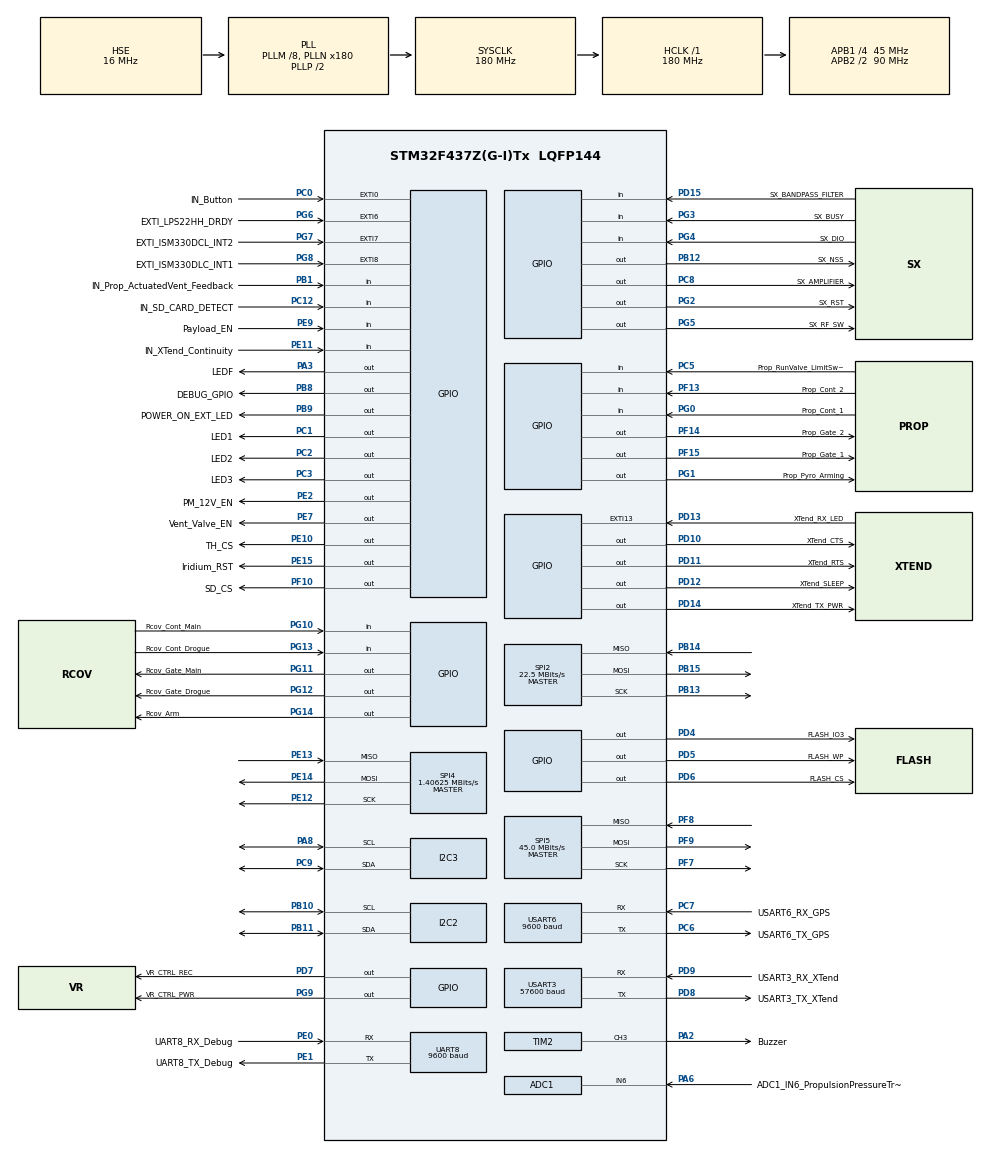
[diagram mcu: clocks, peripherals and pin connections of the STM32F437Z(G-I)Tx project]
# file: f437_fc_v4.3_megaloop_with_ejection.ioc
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ADC1.Channel-0\#ChannelRegularConversion=ADC_CHANNEL_6
ADC1.ClockPrescaler=ADC_CLOCK_SYNC_PCLK_DIV4
ADC1.ContinuousConvMode=DISABLE
ADC1.DMAContinuousRequests=DISABLE
ADC1.ExternalTrigConv=ADC_SOFTWARE_START
ADC1.ExternalTrigConvEdge=ADC_EXTERNALTRIGCONVEDGE_NONE
ADC1.InjNumberOfConversion=0
ADC1.NbrOfConversion=1
ADC1.NbrOfConversionFlag=1
ADC1.Rank-0\#ChannelRegularConversion=1
ADC1.SamplingTime-0\#ChannelRegularConversion=ADC_SAMPLETIME_28CYCLES
ADC1.master=1
Dma.ADC1.3.Direction=DMA_PERIPH_TO_MEMORY
Dma.ADC1.3.FIFOMode=DMA_FIFOMODE_DISABLE
Dma.ADC1.3.Instance=DMA2_Stream0
Dma.ADC1.3.MemDataAlignment=DMA_MDATAALIGN_HALFWORD
Dma.ADC1.3.MemInc=DMA_MINC_ENABLE
Dma.ADC1.3.Mode=DMA_NORMAL
Dma.ADC1.3.PeriphDataAlignment=DMA_PDATAALIGN_HALFWORD
Dma.ADC1.3.PeriphInc=DMA_PINC_DISABLE
Dma.ADC1.3.Priority=DMA_PRIORITY_LOW
Dma.Request0=USART3_RX
Dma.Request1=USART3_TX
Dma.Request2=USART6_RX
Dma.Request3=ADC1
Dma.USART3_RX.0.Direction=DMA_PERIPH_TO_MEMORY
Dma.USART3_RX.0.FIFOMode=DMA_FIFOMODE_DISABLE
Dma.USART3_RX.0.Instance=DMA1_Stream1
Dma.USART3_RX.0.MemDataAlignment=DMA_MDATAALIGN_BYTE
Dma.USART3_RX.0.MemInc=DMA_MINC_ENABLE
Dma.USART3_RX.0.Mode=DMA_NORMAL
Dma.USART3_RX.0.PeriphDataAlignment=DMA_PDATAALIGN_BYTE
Dma.USART3_RX.0.PeriphInc=DMA_PINC_DISABLE
Dma.USART3_RX.0.Priority=DMA_PRIORITY_VERY_HIGH
Dma.USART3_TX.1.Direction=DMA_MEMORY_TO_PERIPH
Dma.USART3_TX.1.FIFOMode=DMA_FIFOMODE_DISABLE
Dma.USART3_TX.1.Instance=DMA1_Stream3
Dma.USART3_TX.1.MemDataAlignment=DMA_MDATAALIGN_BYTE
Dma.USART3_TX.1.MemInc=DMA_MINC_ENABLE
Dma.USART3_TX.1.Mode=DMA_NORMAL
Dma.USART3_TX.1.PeriphDataAlignment=DMA_PDATAALIGN_BYTE
Dma.USART3_TX.1.PeriphInc=DMA_PINC_DISABLE
Dma.USART3_TX.1.Priority=DMA_PRIORITY_MEDIUM
Dma.USART6_RX.2.Direction=DMA_PERIPH_TO_MEMORY
Dma.USART6_RX.2.FIFOMode=DMA_FIFOMODE_DISABLE
Dma.USART6_RX.2.Instance=DMA2_Stream1
Dma.USART6_RX.2.MemDataAlignment=DMA_MDATAALIGN_BYTE
Dma.USART6_RX.2.MemInc=DMA_MINC_ENABLE
Dma.USART6_RX.2.Mode=DMA_NORMAL
Dma.USART6_RX.2.PeriphDataAlignment=DMA_PDATAALIGN_BYTE
Dma.USART6_RX.2.PeriphInc=DMA_PINC_DISABLE
Dma.USART6_RX.2.Priority=DMA_PRIORITY_MEDIUM
IWDG.Prescaler=IWDG_PRESCALER_64
IWDG.Reload=1000-1
Mcu.Family=STM32F4
Mcu.Name=STM32F437Z(G-I)Tx
Mcu.Package=LQFP144
NVIC.DMA1_Stream1_IRQn=true\:15\:0\:true\:false\:true\:false\:true
NVIC.DMA1_Stream3_IRQn=true\:0\:0\:true\:false\:true\:false\:true
NVIC.DMA2_Stream0_IRQn=true\:0\:0\:false\:false\:true\:false\:true
NVIC.DMA2_Stream1_IRQn=true\:0\:0\:false\:false\:true\:false\:true
NVIC.EXTI0_IRQn=true\:0\:0\:false\:false\:true\:true\:true
NVIC.PriorityGroup=NVIC_PRIORITYGROUP_4
NVIC.RTC_Alarm_IRQn=true\:0\:0\:false\:false\:true\:true\:true
NVIC.RTC_WKUP_IRQn=true\:0\:0\:false\:false\:true\:true\:true
NVIC.TIM3_IRQn=true\:0\:0\:true\:false\:true\:true\:true
NVIC.TIM8_BRK_TIM12_IRQn=true\:0\:0\:false\:false\:true\:true\:true
NVIC.TIM8_UP_TIM13_IRQn=true\:0\:0\:false\:false\:true\:true\:true
NVIC.USART3_IRQn=true\:0\:0\:false\:false\:true\:true\:true
NVIC.USART6_IRQn=true\:0\:0\:false\:false\:true\:true\:true
PA13.Mode=Trace_Asynchronous_SW
PA13.Signal=SYS_JTMS-SWDIO
PA14.Mode=Trace_Asynchronous_SW
PA14.Signal=SYS_JTCK-SWCLK
PA2.GPIO_Label=Buzzer
PA2.Signal=S_TIM2_CH3
PA3.GPIO_Label=LEDF
PA3.Signal=GPIO_Output
PA6.GPIO_Label=ADC1_IN6_PropulsionPressureTransducer
PA6.Signal=ADCx_IN6
PA8.GPIO_Pu=GPIO_PULLUP
PA8.Mode=I2C
PA8.Signal=I2C3_SCL
PB1.GPIO_Label=IN_Prop_ActuatedVent_Feedback
PB1.Signal=GPIO_Input
PB10.GPIO_Pu=GPIO_PULLUP
PB10.Mode=I2C
PB10.Signal=I2C2_SCL
PB11.GPIO_Pu=GPIO_PULLUP
PB11.Mode=I2C
PB11.Signal=I2C2_SDA
PB12.GPIO_Label=SX_NSS
PB12.GPIO_PuPd=GPIO_PULLUP
PB12.Signal=GPIO_Output
PB13.GPIO_PuPd=GPIO_PULLUP
PB13.Mode=Full_Duplex_Master
PB13.Signal=SPI2_SCK
PB14.GPIO_PuPd=GPIO_PULLUP
PB14.Mode=Full_Duplex_Master
PB14.Signal=SPI2_MISO
PB15.GPIO_PuPd=GPIO_PULLUP
PB15.Mode=Full_Duplex_Master
PB15.Signal=SPI2_MOSI
PB3.Mode=Trace_Asynchronous_SW
PB3.Signal=SYS_JTDO-SWO
PB8.GPIO_Label=DEBUG_GPIO
PB8.Signal=GPIO_Output
PB9.GPIO_Label=POWER_ON_EXT_LED
PB9.Signal=GPIO_Output
PC0.GPIO_Label=IN_Button
PC0.Signal=GPXTI0
PC1.GPIO_Label=LED1
PC1.Signal=GPIO_Output
PC12.GPIO_Label=IN_SD_CARD_DETECT
PC12.Signal=GPIO_Input
PC14/OSC32_IN.Mode=LSE-External-Oscillator
PC14/OSC32_IN.Signal=RCC_OSC32_IN
PC15/OSC32_OUT.Mode=LSE-External-Oscillator
PC15/OSC32_OUT.Signal=RCC_OSC32_OUT
PC2.GPIO_Label=LED2
PC2.Signal=GPIO_Output
PC3.GPIO_Label=LED3
PC3.Signal=GPIO_Output
PC5.GPIO_Label=Prop_RunValve_LimitSwitch
PC5.GPIO_PuPd=GPIO_PULLDOWN
PC5.Signal=GPIO_Input
PC6.GPIO_Label=USART6_TX_GPS
PC6.Mode=Asynchronous
PC6.Signal=USART6_TX
PC7.GPIO_Label=USART6_RX_GPS
PC7.Mode=Asynchronous
PC7.Signal=USART6_RX
PC8.GPIO_Label=SX_AMPLIFIER
PC8.Signal=GPIO_Output
PC9.GPIO_Pu=GPIO_PULLUP
PC9.Mode=I2C
PC9.Signal=I2C3_SDA
PD10.GPIO_Label=XTend_CTS
PD10.Signal=GPIO_Output
PD11.GPIO_Label=XTend_RTS
PD11.Signal=GPIO_Output
PD12.GPIO_Label=XTend_SLEEP
PD12.Signal=GPIO_Output
PD13.GPIO_Label=XTend_RX_LED
PD13.Signal=GPXTI13
PD14.GPIO_Label=XTend_TX_PWR
PD14.Signal=GPIO_Output
PD15.GPIO_Label=SX_BANDPASS_FILTER
PD15.Signal=GPIO_Input
PD4.GPIO_Label=FLASH_IO3
PD4.GPIO_PuPd=GPIO_PULLUP
PD4.GPIO_Speed=GPIO_SPEED_FREQ_HIGH
PD4.PinState=GPIO_PIN_SET
PD4.Signal=GPIO_Output
PD5.GPIO_Label=FLASH_WP
PD5.GPIO_PuPd=GPIO_PULLUP
PD5.GPIO_Speed=GPIO_SPEED_FREQ_HIGH
PD5.PinState=GPIO_PIN_SET
PD5.Signal=GPIO_Output
PD6.GPIO_Label=FLASH_CS
PD6.GPIO_ModeDefaultOutputPP=GPIO_MODE_OUTPUT_PP
PD6.GPIO_PuPd=GPIO_PULLUP
PD6.GPIO_Speed=GPIO_SPEED_FREQ_VERY_HIGH
PD6.PinState=GPIO_PIN_SET
PD6.Signal=GPIO_Output
PD7.GPIO_Label=VR_CTRL_REC
PD7.Signal=GPIO_Output
PD8.GPIO_Label=USART3_TX_XTend
PD8.Mode=Asynchronous
PD8.Signal=USART3_TX
PD9.GPIO_Label=USART3_RX_XTend
PD9.Mode=Asynchronous
PD9.Signal=USART3_RX
PE0.GPIO_Label=UART8_RX_Debug
PE0.Mode=Asynchronous
PE0.Signal=UART8_RX
PE1.GPIO_Label=UART8_TX_Debug
PE1.Mode=Asynchronous
PE1.Signal=UART8_TX
PE10.GPIO_Label=TH_CS
PE10.Signal=GPIO_Output
PE11.GPIO_Label=IN_XTend_Continuity
PE11.Signal=GPIO_Input
PE12.Mode=Full_Duplex_Master
PE12.Signal=SPI4_SCK
PE13.Mode=Full_Duplex_Master
PE13.Signal=SPI4_MISO
PE14.Mode=Full_Duplex_Master
PE14.Signal=SPI4_MOSI
PE15.GPIO_Label=Iridium_RST
PE15.Signal=GPIO_Output
PE2.GPIO_Label=PM_12V_EN
PE2.Signal=GPIO_Output
PE7.GPIO_Label=Vent_Valve_EN
PE7.Signal=GPIO_Output
PE9.GPIO_Label=Payload_EN
PE9.Signal=GPIO_Input
PF10.GPIO_Label=SD_CS
PF10.GPIO_PuPd=GPIO_PULLUP
PF10.GPIO_Speed=GPIO_SPEED_FREQ_VERY_HIGH
PF10.PinState=GPIO_PIN_SET
PF10.Signal=GPIO_Output
PF13.GPIO_Label=Prop_Cont_2
PF13.Signal=GPIO_Input
PF14.GPIO_Label=Prop_Gate_2
PF14.Signal=GPIO_Output
PF15.GPIO_Label=Prop_Gate_1
PF15.Signal=GPIO_Output
PF7.GPIO_PuPd=GPIO_PULLUP
PF7.GPIO_Speed=GPIO_SPEED_FREQ_VERY_HIGH
PF7.Mode=Full_Duplex_Master
PF7.Signal=SPI5_SCK
PF8.GPIO_PuPd=GPIO_PULLUP
PF8.GPIO_Speed=GPIO_SPEED_FREQ_VERY_HIGH
PF8.Mode=Full_Duplex_Master
PF8.Signal=SPI5_MISO
PF9.GPIO_PuPd=GPIO_PULLUP
PF9.GPIO_Speed=GPIO_SPEED_FREQ_VERY_HIGH
PF9.Mode=Full_Duplex_Master
PF9.Signal=SPI5_MOSI
PG0.GPIO_Label=Prop_Cont_1
PG0.Signal=GPIO_Input
PG1.GPIO_Label=Prop_Pyro_Arming
PG1.Signal=GPIO_Output
PG10.GPIO_Label=Rcov_Cont_Main
PG10.Signal=GPIO_Input
PG11.GPIO_Label=Rcov_Gate_Main
PG11.Signal=GPIO_Output
PG12.GPIO_Label=Rcov_Gate_Drogue
PG12.Signal=GPIO_Output
PG13.GPIO_Label=Rcov_Cont_Drogue
PG13.Signal=GPIO_Input
PG14.GPIO_Label=Rcov_Arm
PG14.Signal=GPIO_Output
PG2.GPIO_Label=SX_RST
PG2.Signal=GPIO_Output
PG3.GPIO_Label=SX_BUSY
PG3.Signal=GPIO_Input
PG4.GPIO_Label=SX_DIO
PG4.Signal=GPIO_Input
PG5.GPIO_Label=SX_RF_SW
PG5.Signal=GPIO_Output
PG6.GPIO_Label=EXTI_LPS22HH_DRDY
PG6.Signal=GPXTI6
PG7.GPIO_Label=EXTI_ISM330DCL_INT2
PG7.Signal=GPXTI7
PG8.GPIO_Label=EXTI_ISM330DLC_INT1
PG8.Signal=GPXTI8
PG9.GPIO_Label=VR_CTRL_PWR
PG9.Signal=GPIO_Output
PH0/OSC_IN.Mode=HSE-External-Oscillator
PH0/OSC_IN.Signal=RCC_OSC_IN
PH1/OSC_OUT.Mode=HSE-External-Oscillator
PH1/OSC_OUT.Signal=RCC_OSC_OUT
ProjectManager.HeapSize=0x200
ProjectManager.StackSize=0x400
ProjectManager.TargetToolchain=STM32CubeIDE
RCC.48MHZClocksFreq_Value=90000000
RCC.AHBFreq_Value=180000000
RCC.APB1CLKDivider=RCC_HCLK_DIV4
RCC.APB1Freq_Value=45000000
RCC.APB1TimFreq_Value=90000000
RCC.APB2CLKDivider=RCC_HCLK_DIV2
RCC.APB2Freq_Value=90000000
RCC.APB2TimFreq_Value=180000000
RCC.CortexFreq_Value=180000000
RCC.HCLKFreq_Value=180000000
RCC.HSE_VALUE=16000000
RCC.HSI_VALUE=16000000
RCC.PLLM=8
RCC.PLLN=180
RCC.PLLSourceVirtual=RCC_PLLSOURCE_HSE
RCC.SYSCLKFreq_VALUE=180000000
RCC.SYSCLKSource=RCC_SYSCLKSOURCE_PLLCLK
RCC.VCOOutputFreq_Value=360000000
RTC.Alarm=RTC_ALARM_A
RTC.Alarm_B=RTC_ALARM_B
RTC.Date=12
RTC.Hours=10
RTC.Minutes=20
RTC.Month=RTC_MONTH_FEBRUARY
RTC.Seconds=30
RTC.Seconds_A=15
RTC.Seconds_B=45
RTC.WakeUpCounter=1333-1
RTC.Year=21
SH.ADCx_IN6.0=ADC1_IN6,IN6
SH.S_TIM2_CH3.0=TIM2_CH3,PWM Generation3 CH3
SPI2.BaudRatePrescaler=SPI_BAUDRATEPRESCALER_2
SPI2.CalculateBaudRate=22.5 MBits/s
SPI2.Direction=SPI_DIRECTION_2LINES
SPI2.Mode=SPI_MODE_MASTER
SPI2.VirtualType=VM_MASTER
SPI4.BaudRatePrescaler=SPI_BAUDRATEPRESCALER_64
SPI4.CalculateBaudRate=1.40625 MBits/s
SPI4.Direction=SPI_DIRECTION_2LINES
SPI4.Mode=SPI_MODE_MASTER
SPI4.VirtualType=VM_MASTER
SPI5.BaudRatePrescaler=SPI_BAUDRATEPRESCALER_2
SPI5.CalculateBaudRate=45.0 MBits/s
SPI5.Direction=SPI_DIRECTION_2LINES
SPI5.Mode=SPI_MODE_MASTER
SPI5.VirtualType=VM_MASTER
TIM12.Period=1000-1
TIM12.Prescaler=900-1
TIM2.Channel-PWM\ Generation3\ CH3=TIM_CHANNEL_3
TIM2.Period=400-1
TIM2.Prescaler=90-1
TIM2.Pulse-PWM\ Generation3\ CH3=100
TIM2.TIM_MasterOutputTrigger=TIM_TRGO_UPDATE
TIM3.AutoReloadPreload=TIM_AUTORELOAD_PRELOAD_DISABLE
TIM3.Period=1000-1
TIM3.Prescaler=9000-1
TIM3.TIM_MasterOutputTrigger=TIM_TRGO_RESET
TIM4.Period=500-1
TIM4.Prescaler=9000-1
TIM4.TIM_MasterOutputTrigger=TIM_TRGO_UPDATE
TIM8.Period=200-1
TIM8.Prescaler=18000-1
TIM8.TIM_MasterOutputTrigger=TIM_TRGO_UPDATE
UART8.BaudRate=9600
UART8.VirtualMode=Asynchronous
USART3.BaudRate=57600
USART3.VirtualMode=VM_ASYNC
USART6.BaudRate=9600
USART6.VirtualMode=VM_ASYNC
VP_FATFS_VS_Generic.Mode=User_defined
VP_IWDG_VS_IWDG.Mode=IWDG_Activate
VP_RTC_VS_RTC_Activate.Mode=RTC_Enabled
VP_RTC_VS_RTC_Alarm_A_Intern.Mode=Alarm A
VP_RTC_VS_RTC_Alarm_B_Intern.Mode=Alarm B
VP_RTC_VS_RTC_Calendar.Mode=RTC_Calendar
VP_RTC_VS_RTC_WakeUp_intern.Mode=WakeUp
VP_TIM12_VS_ClockSourceINT.Mode=Internal
VP_TIM2_VS_ClockSourceINT.Mode=Internal
VP_TIM3_VS_ClockSourceINT.Mode=Internal
VP_TIM4_VS_ClockSourceINT.Mode=Internal
VP_TIM8_VS_ClockSourceINT.Mode=Internal
board=custom

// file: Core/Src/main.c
/* USER CODE BEGIN Header */
/**
  ******************************************************************************
  * @file           : main.c
  * @brief          : Main program body
  ******************************************************************************
  * @attention
  *
  * <h2><center>&copy; Copyright (c) 2022 STMicroelectronics.
  * All rights reserved.</center></h2>
  *
  * This software component is licensed by ST under BSD 3-Clause license,
  * the "License"; You may not use this file except in compliance with the
  * License. You may obtain a copy of the License at:
  *                        opensource.org/licenses/BSD-3-Clause
  *
  ******************************************************************************
  */
/* USER CODE END Header */
#include "main.h"
#include "adc.h"
#include "dma.h"
#include "fatfs.h"
#include "i2c.h"
#include "iwdg.h"
#include "rtc.h"
#include "spi.h"
#include "tim.h"
#include "usart.h"
#include "gpio.h"

/* USER CODE BEGIN Includes */

#include "string.h"

#include "i2c_sensor_functions.h"
#include "sd_card.h"
#include "gps.h"

// xtend radio
#include "xtend.h"

// others
#include "video_recorder.h"
#include "ejection.h"
#include "radio_commands.h"
#include "helpers.h"
#include "state_restoration.h"
#include "telemetry.h"
#include "startup.h"
#include "int_callbacks.h"
#include <iwdg.h>

#ifdef NEW_ADC
#include <MRT_ADS1015.h>
#endif

/* USER CODE END Includes */

/* USER CODE BEGIN PTD */

//#define DEBUG_MODE

/* USER CODE END PTD */

/* USER CODE BEGIN PV */

// flags
volatile uint8_t button_pressed = 0;
volatile uint8_t gps_dma_ready = 0;
volatile uint8_t xtend_time_to_transmit_flag = 0;
volatile uint8_t xtend_is_transmitting = 0;
volatile uint8_t save_sd_fsync = 0;
volatile uint8_t run_main_loop = 0;

extern volatile uint8_t vr_is_stop;
/* USER CODE END PV */

void SystemClock_Config(void);

/* USER CODE BEGIN 0 */

//TODO no print function
void no_print(char* text){
	return;
}

/* USER CODE END 0 */

int main(void)
{

  /* MCU Configuration--------------------------------------------------------*/

  /* Reset of all peripherals, Initializes the Flash interface and the Systick. */
  HAL_Init();

  /* Configure the system clock */
  SystemClock_Config();

  /* USER CODE BEGIN SysInit */
  __HAL_DBGMCU_FREEZE_IWDG();	// turn off IWDG and RTC during debugging
  __HAL_FREEZE_RTC_DBGMCU();
  /* USER CODE END SysInit */

  /* Initialize all configured peripherals */
  MX_GPIO_Init();
  MX_DMA_Init();
  MX_ADC1_Init();
  MX_I2C2_Init();
  MX_I2C3_Init();
  MX_SPI2_Init();
  MX_SPI4_Init();
  MX_SPI5_Init();
  MX_TIM2_Init();
  MX_UART8_Init();
  MX_USART3_UART_Init();
  MX_USART6_UART_Init();
  MX_FATFS_Init();
  MX_RTC_Init();
  MX_TIM4_Init();
  MX_TIM3_Init();
  MX_TIM8_Init();
  MX_IWDG_Init();
  MX_TIM12_Init();
  /* USER CODE BEGIN 2 */

  // *** IMPORTANT: DMA Init function must be called before peripheral init! *** //

  init_gpio_startup(__HAL_RCC_GET_FLAG(RCC_FLAG_IWDGRST));

  if (!(__HAL_RCC_GET_FLAG(RCC_FLAG_IWDGRST))) {
	  init_ejection_states();
	  init_backup_regs();
  }
  else {
	  __HAL_IWDG_RELOAD_COUNTER(&hiwdg);
	  restore_fc_states();

	  sprintf((char *)msg, "state = %d, ap = %d, ar = %d, alt_ground = %f",
			  state_flight, state_arm_prop, state_arm_rcov, alt_ground);
	  debug_tx_uart(msg);

	  // for debug
	  for (uint8_t i = 0; i < 3; i++) {
		  __HAL_IWDG_RELOAD_COUNTER(&hiwdg);
		  HAL_GPIO_WritePin(LED1_GPIO_Port, LED1_Pin, SET);
		  HAL_GPIO_WritePin(LED2_GPIO_Port, LED2_Pin, SET);
		  HAL_GPIO_WritePin(LED3_GPIO_Port, LED3_Pin, SET);
		  HAL_GPIO_WritePin(LEDF_GPIO_Port, LEDF_Pin, SET);

		  HAL_Delay(100);

		  HAL_GPIO_WritePin(LED1_GPIO_Port, LED1_Pin, RESET);
		  HAL_GPIO_WritePin(LED2_GPIO_Port, LED2_Pin, RESET);
		  HAL_GPIO_WritePin(LED3_GPIO_Port, LED3_Pin, RESET);
		  HAL_GPIO_WritePin(LEDF_GPIO_Port, LEDF_Pin, RESET);

		  HAL_Delay(100);
	  }
  }

  #ifndef USING_XTEND
	  set_hspi(hspi2);
	  set_NSS_pin(SX_NSS_GPIO_Port, SX_NSS_Pin);
	  set_BUSY_pin(SX_BUSY_GPIO_Port, SX_BUSY_Pin);
	  set_NRESET_pin(SX_RST_GPIO_Port, SX_RST_Pin);
	  set_DIO1_pin(SX_DIO_GPIO_Port, SX_DIO_Pin);
	  Tx_setup();
  #endif

  dev_ctx_lsm = lsm6dsl_init();
  dev_ctx_lps = lps22hh_init();

  //TODO new ADC
  #ifdef NEW_ADC
  __HAL_IWDG_RELOAD_COUNTER(&hiwdg);
  hadc1015 = MRT_ADC1015_Init(ADC_I2C,no_print);
  #endif

  sd_init_dynamic_filename("TE", sd_file_header, filename);
  GPS_StartDMA();
  xtend_init();

  __HAL_IWDG_RELOAD_COUNTER(&hiwdg);
  telemetry_init();

  if (!(__HAL_RCC_GET_FLAG(RCC_FLAG_IWDGRST))) {
	  buzz_startup_success();	// got to this point, successful init

	  // get ground altitude
	  for (uint8_t i = 0; i < 100; i++) { // ALT_MEAS_AVGING defined in main.h
		  alt_ground += getAltitude();
	  }
	  alt_ground /= ((float) (100));
	  set_backup_state(FC_STATE_ALT_GROUND, (uint32_t) alt_ground);
	  alt_current = alt_ground;
  }

  sprintf((char *)msg_buffer_av, "alt_ground=%.3f\r\n\n", alt_ground);
  fres = sd_open_file(filename);
  sd_write(&fil, msg_buffer_av);
  if (state_flight < EJ_STATE_DROGUE_DESCENT) {
	  sd_write(&fil, msg_buffer_pr);
  }
  memset(msg_buffer_av, 0, 200);

  // start timers:
  HAL_TIM_Base_Start_IT(&XTEND_TIM_H);	// drives XTend transmitting
  //HAL_TIM_Base_Start_IT(&htim8);		// drives ADC TODO remove
  HAL_TIM_Base_Start_IT(&htim12);		// drives main while loop

  __HAL_RCC_CLEAR_RESET_FLAGS();		// clear RCC reset flags

  HAL_GPIO_WritePin(DEBUG_GPIO_GPIO_Port, DEBUG_GPIO_Pin, RESET);

  /* USER CODE END 2 */

  /* Infinite loop */
  /* USER CODE BEGIN WHILE */

  while (1)
  {
		if (run_main_loop) {

			run_main_loop = 0;
			__HAL_IWDG_RELOAD_COUNTER(&hiwdg); // refresh watchdog

			read_update_telemetry_av();

			if (state_flight < EJ_STATE_DROGUE_DESCENT) { // propulsion data (not needed after apogee)
				read_update_telemetry_pr();
				telemetry_format_propulsion();
			}

			telemetry_format_avionics();

			sd_write(&fil, msg_buffer_av);
			if (state_flight < EJ_STATE_DROGUE_DESCENT) {
				sd_write(&fil, msg_buffer_pr);
			}

			if (save_sd_fsync) {
				save_sd_fsync = 0;
				f_sync(&fil);
			}

		#ifdef DEBUG_MODE
//			debug_tx_uart(msg_buffer_av);
//			debug_tx_uart(msg_buffer_pr);
			sprintf(msg, "states of fc: s=%d, ap=%d, ar=%d, HH:MM:SS = %02d:%02d:%02d\r\n",
				   state_flight, state_arm_prop, state_arm_rcov,
				   stimeget.Hours, stimeget.Minutes, stimeget.Seconds);
			debug_tx_uart(msg);
		#endif

			if (xtend_time_to_transmit_flag) {
				xtend_time_to_transmit_flag = 0;
				xtend_transmit_telemetry(state_flight);
			}

			check_ejection_state(); // check which state of flight we are in

			__HAL_IWDG_RELOAD_COUNTER(&hiwdg);

			if (sleepmode == 1) { // stop mode after landing

				__HAL_PWR_CLEAR_FLAG(PWR_FLAG_WU);
//				HAL_RTCEx_SetWakeUpTimer_IT(&hrtc, 2000-1, RTC_WAKEUPCLOCK_RTCCLK_DIV16);
				HAL_RTCEx_SetWakeUpTimer_IT(&hrtc, 20000-1, RTC_WAKEUPCLOCK_RTCCLK_DIV16);
				HAL_PWR_EnableSleepOnExit();
				HAL_SuspendTick();
				HAL_PWR_EnterSTOPMode(PWR_LOWPOWERREGULATOR_ON, PWR_STOPENTRY_WFI);
			}
			else if (sleepmode == 2) { // sleep mode on pad
				__HAL_PWR_CLEAR_FLAG(PWR_FLAG_WU);
//				HAL_RTCEx_SetWakeUpTimer_IT(&hrtc, 2000-1, RTC_WAKEUPCLOCK_RTCCLK_DIV16);
				HAL_RTCEx_SetWakeUpTimer_IT(&hrtc, 20000-1, RTC_WAKEUPCLOCK_RTCCLK_DIV16);

				HAL_TIM_Base_Stop_IT(&XTEND_TIM_H);
				HAL_TIM_Base_Stop_IT(&htim8);
				HAL_TIM_Base_Stop_IT(&htim12);

				HAL_PWR_EnableSleepOnExit();
				HAL_SuspendTick();
				HAL_PWR_EnterSLEEPMode(PWR_LOWPOWERREGULATOR_ON, PWR_SLEEPENTRY_WFI);
			}

//			if (state_flight == EJ_STATE_LANDED) {
//				for (uint8_t i = 0; i < 5; i++) { // 5 seconds
//					__HAL_IWDG_RELOAD_COUNTER(&hiwdg);
//					HAL_Delay(1000); // slow it down
//				}
//			}

//			if (vr_is_stop) {
//				vr_is_stop = 0;
//
//				HAL_GPIO_WritePin(VR_CTRL_REC_GPIO_Port, VR_CTRL_REC_Pin, SET);
//				HAL_Delay(1000);
//				HAL_GPIO_WritePin(VR_CTRL_REC_GPIO_Port, VR_CTRL_REC_Pin, RESET);
//			}
		}

    /* USER CODE END WHILE */

  }
}

void SystemClock_Config(void)
{
  RCC_OscInitTypeDef RCC_OscInitStruct = {0};
  RCC_ClkInitTypeDef RCC_ClkInitStruct = {0};

  /** Configure the main internal regulator output voltage
  */
  __HAL_RCC_PWR_CLK_ENABLE();
  __HAL_PWR_VOLTAGESCALING_CONFIG(PWR_REGULATOR_VOLTAGE_SCALE1);
  /** Initializes the RCC Oscillators according to the specified parameters
  * in the RCC_OscInitTypeDef structure.
  */
  RCC_OscInitStruct.OscillatorType = RCC_OSCILLATORTYPE_LSI|RCC_OSCILLATORTYPE_HSE;
  RCC_OscInitStruct.HSEState = RCC_HSE_ON;
  RCC_OscInitStruct.LSIState = RCC_LSI_ON;
  RCC_OscInitStruct.PLL.PLLState = RCC_PLL_ON;
  RCC_OscInitStruct.PLL.PLLSource = RCC_PLLSOURCE_HSE;
  RCC_OscInitStruct.PLL.PLLM = 8;
  RCC_OscInitStruct.PLL.PLLN = 180;
  RCC_OscInitStruct.PLL.PLLP = RCC_PLLP_DIV2;
  RCC_OscInitStruct.PLL.PLLQ = 4;
  if (HAL_RCC_OscConfig(&RCC_OscInitStruct) != HAL_OK)
  {
    Error_Handler();
  }
  /** Activate the Over-Drive mode
  */
  if (HAL_PWREx_EnableOverDrive() != HAL_OK)
  {
    Error_Handler();
  }
  /** Initializes the CPU, AHB and APB buses clocks
  */
  RCC_ClkInitStruct.ClockType = RCC_CLOCKTYPE_HCLK|RCC_CLOCKTYPE_SYSCLK
                              |RCC_CLOCKTYPE_PCLK1|RCC_CLOCKTYPE_PCLK2;
  RCC_ClkInitStruct.SYSCLKSource = RCC_SYSCLKSOURCE_PLLCLK;
  RCC_ClkInitStruct.AHBCLKDivider = RCC_SYSCLK_DIV1;
  RCC_ClkInitStruct.APB1CLKDivider = RCC_HCLK_DIV4;
  RCC_ClkInitStruct.APB2CLKDivider = RCC_HCLK_DIV2;

  if (HAL_RCC_ClockConfig(&RCC_ClkInitStruct, FLASH_LATENCY_5) != HAL_OK)
  {
    Error_Handler();
  }
}

void Error_Handler(void)
{
  /* USER CODE BEGIN Error_Handler_Debug */
  /* User can add his own implementation to report the HAL error return state */
	HAL_GPIO_WritePin(LEDF_GPIO_Port, LEDF_Pin, GPIO_PIN_SET);
	while (1) {
		buzz_failure();
	}

  /* USER CODE END Error_Handler_Debug */
}

/************************ (C) COPYRIGHT STMicroelectronics *****END OF FILE****/
